# STM32F407 register map
File version: 1.2
CPU: CM4 r1p0, little endian, no MPU, no FPU, 4 interrupt priority bits
Registers are 32-bit, read-write, reset 0x0 unless marked. A register's access mark holds for its fields unless they carry their own. Offsets are from the block's base; [hi:lo] are bit positions; {n}, {i} and the like mark numbered series; 'fields as' and 'values as' point back to an identical list.

## RCC — Reset and clock control
Base 0x40023800
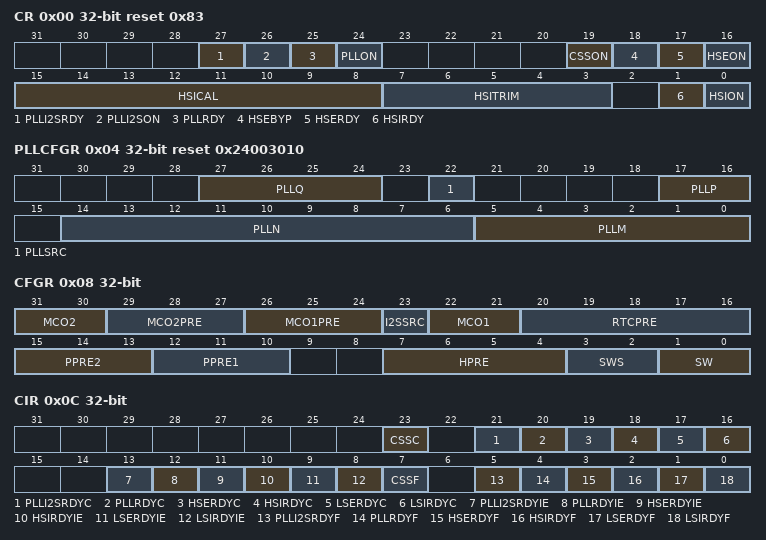
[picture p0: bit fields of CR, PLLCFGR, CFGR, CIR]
0x00 CR access per field reset 0x83 — clock control register
  [27] PLLI2SRDY ro — PLLI2S clock ready flag
    on read: 0=NotReady (Clock not ready); 1=Ready (Clock ready)
  [26] PLLI2SON rw — PLLI2S enable
    0=Off (Clock Off); 1=On (Clock On)
  [25] PLLRDY ro — Main PLL (PLL) clock ready flag
    on read: 0=NotReady (Clock not ready); 1=Ready (Clock ready)
  [24] PLLON rw — Main PLL (PLL) enable
    0=Off (Clock Off); 1=On (Clock On)
  [19] CSSON rw — Clock security system enable
    0=Off (Clock security system disabled (clock detector OFF)); 1=On (Clock security system enable (clock detector ON if the HSE is ready, OFF if not))
  [18] HSEBYP rw — HSE clock bypass
    0=NotBypassed (HSE crystal oscillator not bypassed); 1=Bypassed (HSE crystal oscillator bypassed with external clock)
  [17] HSERDY ro — HSE clock ready flag
    on read: 0=NotReady (Clock not ready); 1=Ready (Clock ready)
  [16] HSEON rw — HSE clock enable
    0=Off (Clock Off); 1=On (Clock On)
  [15:8] HSICAL ro — Internal high-speed clock calibration
  [7:3] HSITRIM rw — Internal high-speed clock trimming
  [1] HSIRDY ro — Internal high-speed clock ready flag
    on read: 0=NotReady (Clock not ready); 1=Ready (Clock ready)
  [0] HSION rw — Internal high-speed clock enable
    0=Off (Clock Off); 1=On (Clock On)
0x04 PLLCFGR reset 0x24003010 — PLL configuration register
  [27:24] PLLQ range 2..15 — Main PLL (PLL) division factor for USB OTG FS, SDIO and random number generator clocks
  [22] PLLSRC — Main PLL(PLL) and audio PLL (PLLI2S) entry clock source
    0=HSI (HSI clock selected as PLL and PLLI2S clock entry); 1=HSE (HSE oscillator clock selected as PLL and PLLI2S clock entry)
  [17:16] PLLP — Main PLL (PLL) division factor for main system clock
    0=Div2 (PLLP=2); 1=Div4 (PLLP=4); 2=Div6 (PLLP=6); 3=Div8 (PLLP=8)
  [14:6] PLLN range 50..432 — Main PLL (PLL) multiplication factor for VCO
  [5:0] PLLM range 2..63 — Division factor for the main PLL (PLL) and audio PLL (PLLI2S) input clock
0x08 CFGR access not given — clock configuration register
  [31:30] MCO2 rw — Microcontroller clock output 2
    0=SYSCLK (System clock (SYSCLK) selected); 1=PLLI2S (PLLI2S clock selected); 2=HSE (HSE oscillator clock selected); 3=PLL (PLL clock selected)
  [29:27] MCO2PRE rw — MCO2 prescaler
    0=Div1 (No division); {v}=Div{v-2} (Division by {v-2}) (v=4..7)
  [26:24] MCO1PRE rw — MCO1 prescaler
    values as MCO2PRE
  [23] I2SSRC rw — I2S clock selection
    0=PLLI2S (PLLI2S clock used as I2S clock source); 1=CKIN (External clock mapped on the I2S_CKIN pin used as I2S clock source)
  [22:21] MCO1 rw — Microcontroller clock output 1
    0=HSI (HSI clock selected); 1=LSE (LSE oscillator selected); 2=HSE (HSE oscillator clock selected); 3=PLL (PLL clock selected)
  [20:16] RTCPRE rw — HSE division factor for RTC clock
  [15:13] PPRE2 rw — APB high-speed prescaler (APB2)
    0=Div1 (HCLK not divided); 4=Div2 (HCLK divided by 2); 5=Div4 (HCLK divided by 4); 6=Div8 (HCLK divided by 8); 7=Div16 (HCLK divided by 16)
  [12:10] PPRE1 rw — APB Low speed prescaler (APB1)
    values as PPRE2
  [7:4] HPRE rw — AHB prescaler
    0=Div1 (SYSCLK not divided); 8=Div2 (SYSCLK divided by 2); 9=Div4 (SYSCLK divided by 4); 10=Div8 (SYSCLK divided by 8); 11=Div16 (SYSCLK divided by 16); 12=Div64 (SYSCLK divided by 64); 13=Div128 (SYSCLK divided by 128); 14=Div256 (SYSCLK divided by 256); 15=Div512 (SYSCLK divided by 512)
  [3:2] SWS — System clock switch status
    on read: 0=HSI (HSI oscillator used as system clock); 1=HSE (HSE oscillator used as system clock); 2=PLL (PLL used as system clock)
  [1:0] SW — System clock switch
    0=HSI (HSI selected as system clock); 1=HSE (HSE selected as system clock); 2=PLL (PLL selected as system clock)
0x0C CIR access per field — clock interrupt register
  [23] CSSC wo — Clock security system interrupt clear
    on write: 1=Clear CSSF flag
  [21] PLLI2SRDYC wo — PLLI2S ready interrupt clear
    on write: 1=Clear interrupt flag
  [20] PLLRDYC wo — Main PLL(PLL) ready interrupt clear
    on write: 1=Clear interrupt flag
  [19] HSERDYC wo — HSE ready interrupt clear
    on write: 1=Clear interrupt flag
  [18] HSIRDYC wo — HSI ready interrupt clear
    on write: 1=Clear interrupt flag
  [17] LSERDYC wo — LSE ready interrupt clear
    on write: 1=Clear interrupt flag
  [16] LSIRDYC wo — LSI ready interrupt clear
    on write: 1=Clear interrupt flag
  [13] PLLI2SRDYIE rw — PLLI2S ready interrupt enable
    0=Disabled (Interrupt disabled); 1=Enabled (Interrupt enabled)
  [12] PLLRDYIE rw — Main PLL (PLL) ready interrupt enable
    values as PLLI2SRDYIE
  [11] HSERDYIE rw — HSE ready interrupt enable
    values as PLLI2SRDYIE
  [10] HSIRDYIE rw — HSI ready interrupt enable
    values as PLLI2SRDYIE
  [9] LSERDYIE rw — LSE ready interrupt enable
    values as PLLI2SRDYIE
  [8] LSIRDYIE rw — LSI ready interrupt enable
    values as PLLI2SRDYIE
  [7] CSSF ro — Clock security system interrupt flag
    on read: 0=NotInterrupted (No clock security interrupt caused by HSE clock failure); 1=Interrupted (Clock security interrupt caused by HSE clock failure)
  [5] PLLI2SRDYF ro — PLLI2S ready interrupt flag
    on read: 0=NotInterrupted (No clock ready interrupt); 1=Interrupted (Clock ready interrupt)
  [4] PLLRDYF ro — Main PLL (PLL) ready interrupt flag
    values as PLLI2SRDYF
  [3] HSERDYF ro — HSE ready interrupt flag
    values as PLLI2SRDYF
  [2] HSIRDYF ro — HSI ready interrupt flag
    values as PLLI2SRDYF
  [1] LSERDYF ro — LSE ready interrupt flag
    values as PLLI2SRDYF
  [0] LSIRDYF ro — LSI ready interrupt flag
    values as PLLI2SRDYF
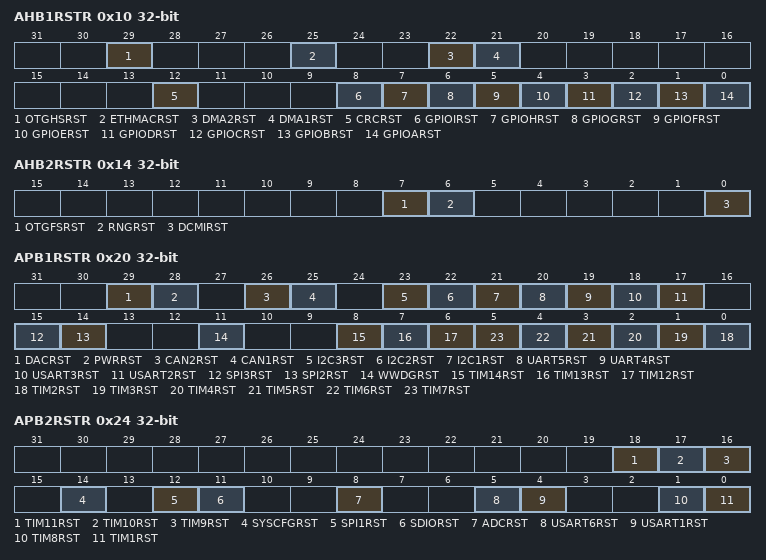
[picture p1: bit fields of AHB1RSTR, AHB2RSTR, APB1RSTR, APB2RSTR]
0x10 AHB1RSTR — AHB1 peripheral reset register
  [all] fields
    1=Reset the selected module
  [29] OTGHSRST — USB OTG HS module reset
  [25] ETHMACRST — Ethernet MAC reset
  [22] DMA2RST — DMA2 reset
  [21] DMA1RST — DMA2 reset
  [12] CRCRST — CRC reset
  [8] GPIOIRST — IO port I reset
  [7] GPIOHRST — IO port H reset
  [6] GPIOGRST — IO port G reset
  [5] GPIOFRST — IO port F reset
  [4] GPIOERST — IO port E reset
  [3] GPIODRST — IO port D reset
  [2] GPIOCRST — IO port C reset
  [1] GPIOBRST — IO port B reset
  [0] GPIOARST — IO port A reset
0x14 AHB2RSTR — AHB2 peripheral reset register
  [all] fields
    1=Reset the selected module
  [7] OTGFSRST — USB OTG FS module reset
  [6] RNGRST — Random number generator module reset
  [0] DCMIRST — Camera interface reset
0x18 AHB3RSTR — AHB3 peripheral reset register
  [0] FSMCRST — Flexible static memory controller module reset
    1=Reset the selected module
0x20 APB1RSTR — APB1 peripheral reset register
  [all] fields
    1=Reset the selected module
  [29] DACRST — DAC reset
  [28] PWRRST — Power interface reset
  [26] CAN2RST — CAN2 reset
  [25] CAN1RST — CAN1 reset
  [23] I2C3RST — I2C3 reset
  [22] I2C2RST — I2C 2 reset
  [21] I2C1RST — I2C 1 reset
  [20] UART5RST — USART 5 reset
  [19] UART4RST — USART 4 reset
  [18] USART3RST — USART 3 reset
  [17] USART2RST — USART 2 reset
  [15] SPI3RST — SPI 3 reset
  [14] SPI2RST — SPI 2 reset
  [11] WWDGRST — Window watchdog reset
  [8] TIM14RST — TIM14 reset
  [7] TIM13RST — TIM13 reset
  [6] TIM12RST — TIM12 reset
  [n-2] TIM{n}RST (n=2..7) — TIM{n} reset
0x24 APB2RSTR — APB2 peripheral reset register
  [all] fields
    1=Reset the selected module
  [18] TIM11RST — TIM11 reset
  [17] TIM10RST — TIM10 reset
  [16] TIM9RST — TIM9 reset
  [14] SYSCFGRST — System configuration controller reset
  [12] SPI1RST — SPI 1 reset
  [11] SDIORST — SDIO reset
  [8] ADCRST — ADC interface reset (common to all ADCs)
  [5] USART6RST — USART6 reset
  [4] USART1RST — USART1 reset
  [1] TIM8RST — TIM8 reset
  [0] TIM1RST — TIM1 reset
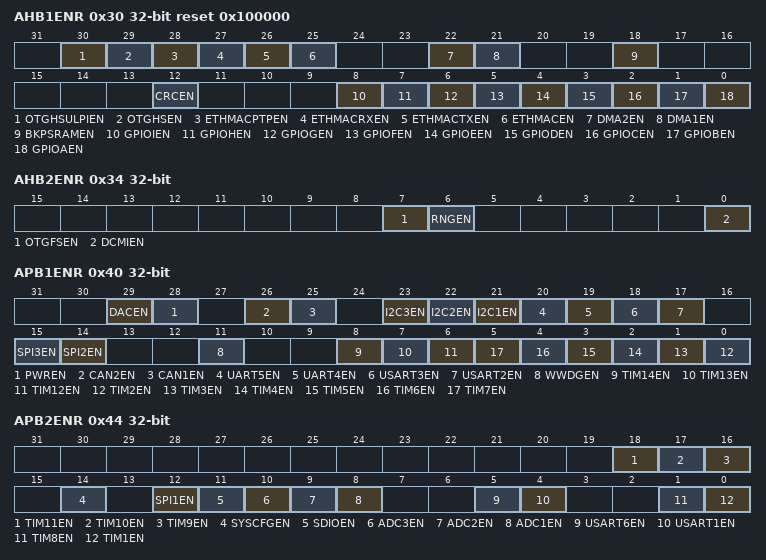
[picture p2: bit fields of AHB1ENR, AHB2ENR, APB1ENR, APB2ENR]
0x30 AHB1ENR reset 0x100000 — AHB1 peripheral clock register
  [all] fields
    0=Disabled (The selected clock is disabled); 1=Enabled (The selected clock is enabled)
  [30] OTGHSULPIEN — USB OTG HSULPI clock enable
  [29] OTGHSEN — USB OTG HS clock enable
  [28] ETHMACPTPEN — Ethernet PTP clock enable
  [27] ETHMACRXEN — Ethernet Reception clock enable
  [26] ETHMACTXEN — Ethernet Transmission clock enable
  [25] ETHMACEN — Ethernet MAC clock enable
  [22] DMA2EN — DMA2 clock enable
  [21] DMA1EN — DMA1 clock enable
  [18] BKPSRAMEN — Backup SRAM interface clock enable
  [12] CRCEN — CRC clock enable
  [8] GPIOIEN — IO port I clock enable
  [7] GPIOHEN — IO port H clock enable
  [6] GPIOGEN — IO port G clock enable
  [5] GPIOFEN — IO port F clock enable
  [4] GPIOEEN — IO port E clock enable
  [3] GPIODEN — IO port D clock enable
  [2] GPIOCEN — IO port C clock enable
  [1] GPIOBEN — IO port B clock enable
  [0] GPIOAEN — IO port A clock enable
0x34 AHB2ENR — AHB2 peripheral clock enable register
  [all] fields
    values as the fields of AHB1ENR
  [7] OTGFSEN — USB OTG FS clock enable
  [6] RNGEN — Random number generator clock enable
  [0] DCMIEN — Camera interface enable
0x38 AHB3ENR — AHB3 peripheral clock enable register
  [0] FSMCEN — Flexible static memory controller module clock enable
    values as the fields of AHB1ENR
0x40 APB1ENR — APB1 peripheral clock enable register
  [all] fields
    values as the fields of AHB1ENR
  [29] DACEN — DAC interface clock enable
  [28] PWREN — Power interface clock enable
  [26] CAN2EN — CAN 2 clock enable
  [25] CAN1EN — CAN 1 clock enable
  [23] I2C3EN — I2C3 clock enable
  [22] I2C2EN — I2C2 clock enable
  [21] I2C1EN — I2C1 clock enable
  [20] UART5EN — UART5 clock enable
  [19] UART4EN — UART4 clock enable
  [18] USART3EN — USART3 clock enable
  [17] USART2EN — USART 2 clock enable
  [15] SPI3EN — SPI3 clock enable
  [14] SPI2EN — SPI2 clock enable
  [11] WWDGEN — Window watchdog clock enable
  [8] TIM14EN — TIM14 clock enable
  [7] TIM13EN — TIM13 clock enable
  [6] TIM12EN — TIM12 clock enable
  [n-2] TIM{n}EN (n=2..7) — TIM{n} clock enable
0x44 APB2ENR — APB2 peripheral clock enable register
  [all] fields
    values as the fields of AHB1ENR
  [18] TIM11EN — TIM11 clock enable
  [17] TIM10EN — TIM10 clock enable
  [16] TIM9EN — TIM9 clock enable
  [14] SYSCFGEN — System configuration controller clock enable
  [12] SPI1EN — SPI1 clock enable
  [11] SDIOEN — SDIO clock enable
  [10] ADC3EN — ADC3 clock enable
  [9] ADC2EN — ADC2 clock enable
  [8] ADC1EN — ADC1 clock enable
  [5] USART6EN — USART6 clock enable
  [4] USART1EN — USART1 clock enable
  [1] TIM8EN — TIM8 clock enable
  [0] TIM1EN — TIM1 clock enable
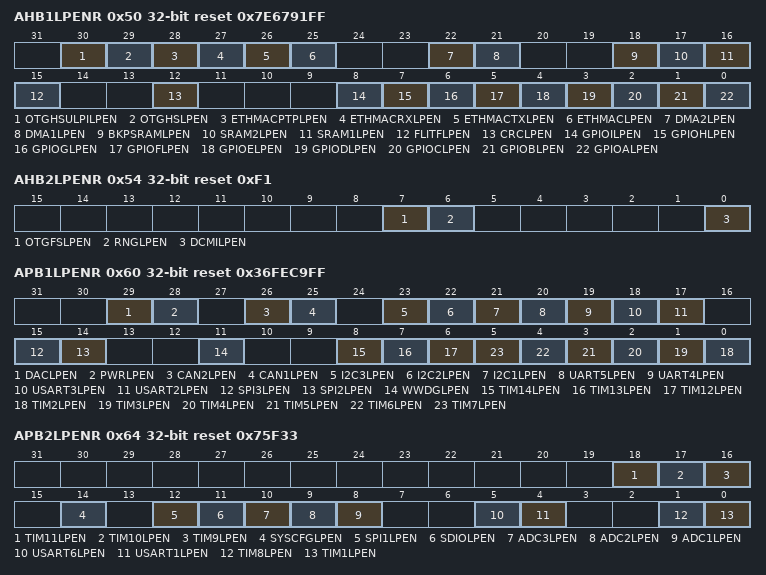
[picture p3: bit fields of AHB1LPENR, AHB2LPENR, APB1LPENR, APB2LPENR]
0x50 AHB1LPENR reset 0x7E6791FF — AHB1 peripheral clock enable in low power mode register
  [all] fields
    0=DisabledInSleep (Selected module is disabled during Sleep mode); 1=EnabledInSleep (Selected module is enabled during Sleep mode)
  [30] OTGHSULPILPEN — USB OTG HS ULPI clock enable during Sleep mode
  [29] OTGHSLPEN — USB OTG HS clock enable during Sleep mode
  [28] ETHMACPTPLPEN — Ethernet PTP clock enable during Sleep mode
  [27] ETHMACRXLPEN — Ethernet reception clock enable during Sleep mode
  [26] ETHMACTXLPEN — Ethernet transmission clock enable during Sleep mode
  [25] ETHMACLPEN — Ethernet MAC clock enable during Sleep mode
  [22] DMA2LPEN — DMA2 clock enable during Sleep mode
  [21] DMA1LPEN — DMA1 clock enable during Sleep mode
  [18] BKPSRAMLPEN — Backup SRAM interface clock enable during Sleep mode
  [17] SRAM2LPEN — SRAM 2 interface clock enable during Sleep mode
  [16] SRAM1LPEN — SRAM 1interface clock enable during Sleep mode
  [15] FLITFLPEN — Flash interface clock enable during Sleep mode
  [12] CRCLPEN — CRC clock enable during Sleep mode
  [8] GPIOILPEN — IO port I clock enable during Sleep mode
  [7] GPIOHLPEN — IO port H clock enable during Sleep mode
  [6] GPIOGLPEN — IO port G clock enable during Sleep mode
  [5] GPIOFLPEN — IO port F clock enable during Sleep mode
  [4] GPIOELPEN — IO port E clock enable during Sleep mode
  [3] GPIODLPEN — IO port D clock enable during Sleep mode
  [2] GPIOCLPEN — IO port C clock enable during Sleep mode
  [1] GPIOBLPEN — IO port B clock enable during Sleep mode
  [0] GPIOALPEN — IO port A clock enable during sleep mode
0x54 AHB2LPENR reset 0xF1 — AHB2 peripheral clock enable in low power mode register
  [all] fields
    values as the fields of AHB1LPENR
  [7] OTGFSLPEN — USB OTG FS clock enable during Sleep mode
  [6] RNGLPEN — Random number generator clock enable during Sleep mode
  [0] DCMILPEN — Camera interface enable during Sleep mode
0x58 AHB3LPENR reset 0x1 — AHB3 peripheral clock enable in low power mode register
  [0] FSMCLPEN — Flexible static memory controller module clock enable during Sleep mode
    values as the fields of AHB1LPENR
0x60 APB1LPENR reset 0x36FEC9FF — APB1 peripheral clock enable in low power mode register
  [all] fields
    values as the fields of AHB1LPENR
  [29] DACLPEN — DAC interface clock enable during Sleep mode
  [28] PWRLPEN — Power interface clock enable during Sleep mode
  [26] CAN2LPEN — CAN 2 clock enable during Sleep mode
  [25] CAN1LPEN — CAN 1 clock enable during Sleep mode
  [23] I2C3LPEN — I2C3 clock enable during Sleep mode
  [22] I2C2LPEN — I2C2 clock enable during Sleep mode
  [21] I2C1LPEN — I2C1 clock enable during Sleep mode
  [20] UART5LPEN — UART5 clock enable during Sleep mode
  [19] UART4LPEN — UART4 clock enable during Sleep mode
  [18] USART3LPEN — USART3 clock enable during Sleep mode
  [17] USART2LPEN — USART2 clock enable during Sleep mode
  [15] SPI3LPEN — SPI3 clock enable during Sleep mode
  [14] SPI2LPEN — SPI2 clock enable during Sleep mode
  [11] WWDGLPEN — Window watchdog clock enable during Sleep mode
  [8] TIM14LPEN — TIM14 clock enable during Sleep mode
  [7] TIM13LPEN — TIM13 clock enable during Sleep mode
  [6] TIM12LPEN — TIM12 clock enable during Sleep mode
  [n-2] TIM{n}LPEN (n=2..7) — TIM{n} clock enable during Sleep mode
0x64 APB2LPENR reset 0x75F33 — APB2 peripheral clock enabled in low power mode register
  [all] fields
    values as the fields of AHB1LPENR
  [18] TIM11LPEN — TIM11 clock enable during Sleep mode
  [17] TIM10LPEN — TIM10 clock enable during Sleep mode
  [16] TIM9LPEN — TIM9 clock enable during sleep mode
  [14] SYSCFGLPEN — System configuration controller clock enable during Sleep mode
  [12] SPI1LPEN — SPI 1 clock enable during Sleep mode
  [11] SDIOLPEN — SDIO clock enable during Sleep mode
  [10] ADC3LPEN — ADC 3 clock enable during Sleep mode
  [9] ADC2LPEN — ADC2 clock enable during Sleep mode
  [8] ADC1LPEN — ADC1 clock enable during Sleep mode
  [5] USART6LPEN — USART6 clock enable during Sleep mode
  [4] USART1LPEN — USART1 clock enable during Sleep mode
  [1] TIM8LPEN — TIM8 clock enable during Sleep mode
  [0] TIM1LPEN — TIM1 clock enable during Sleep mode
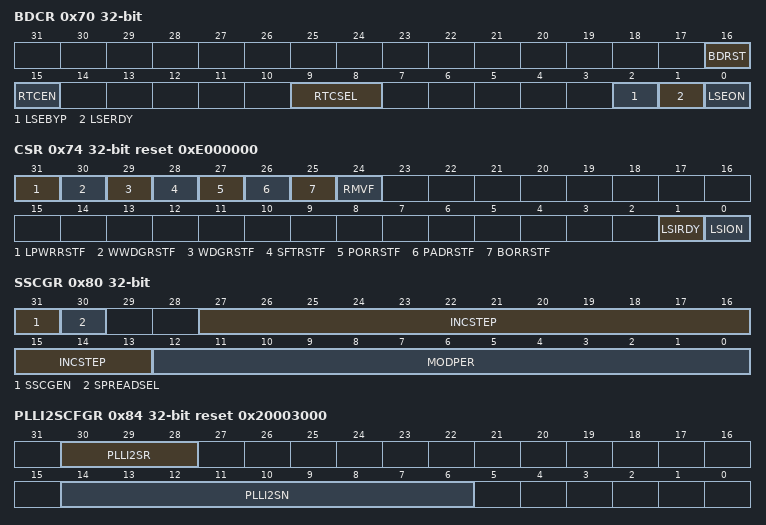
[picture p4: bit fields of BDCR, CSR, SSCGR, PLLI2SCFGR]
0x70 BDCR access not given — Backup domain control register
  [16] BDRST rw — Backup domain software reset
    0=Disabled (Reset not activated); 1=Enabled (Reset the entire RTC domain)
  [15] RTCEN rw — RTC clock enable
    0=Disabled (RTC clock disabled); 1=Enabled (RTC clock enabled)
  [9:8] RTCSEL — RTC clock source selection
    0=NoClock; 1=LSE (LSE oscillator clock used as RTC clock); 2=LSI (LSI oscillator clock used as RTC clock); 3=HSE (HSE oscillator clock divided by a prescaler used as RTC clock)
  [2] LSEBYP rw — External low-speed oscillator bypass
    0=NotBypassed (LSE crystal oscillator not bypassed); 1=Bypassed (LSE crystal oscillator bypassed with external clock)
  [1] LSERDY ro — External low-speed oscillator ready
    on read: 0=NotReady (LSE oscillator not ready); 1=Ready (LSE oscillator ready)
  [0] LSEON rw — External low-speed oscillator enable
    0=Off (LSE oscillator Off); 1=On (LSE oscillator On)
0x74 CSR access per field reset 0xE000000 — clock control & status register
  [31] LPWRRSTF rw — Low-power reset flag
    on read: 0=No reset has occured; 1=Reset (A reset has occured)
  [30] WWDGRSTF rw — Window watchdog reset flag
    values as LPWRRSTF
  [29] WDGRSTF rw — Independent watchdog reset flag
    values as LPWRRSTF
  [28] SFTRSTF rw — Software reset flag
    values as LPWRRSTF
  [27] PORRSTF rw — POR/PDR reset flag
    values as LPWRRSTF
  [26] PADRSTF rw — PIN reset flag
    values as LPWRRSTF
  [25] BORRSTF rw — BOR reset flag
    values as LPWRRSTF
  [24] RMVF rw — Remove reset flag
    on write: 1=Clears the reset flag
  [1] LSIRDY ro — Internal low-speed oscillator ready
    on read: 0=NotReady (LSI oscillator not ready); 1=Ready (LSI oscillator ready)
  [0] LSION rw — Internal low-speed oscillator enable
    0=Off (LSI oscillator Off); 1=On (LSI oscillator On)
0x80 SSCGR — spread spectrum clock generation register
  [31] SSCGEN — Spread spectrum modulation enable
    0=Disabled (Spread spectrum modulation disabled); 1=Enabled (Spread spectrum modulation enabled)
  [30] SPREADSEL — Spread Select
    0=Center spread; 1=Down spread
  [27:13] INCSTEP — Incrementation step
  [12:0] MODPER — Modulation period
0x84 PLLI2SCFGR reset 0x20003000 — PLLI2S configuration register
  [30:28] PLLI2SR range 2..7 — PLLI2S division factor for I2S clocks
  [14:6] PLLI2SN range 50..432 — PLLI2S multiplication factor for VCO
